AUTOSAR XML (schema 4-2-1)
standard types defined: sint32, uint32, uint8, sint32_DataConstr, uint32_DataConstr, uint8_DataConstr, uint16
package /TARefApp0102_SystemPackage/Types
  impl type ECmpCmd: category=VALUE, base-type=DataTypes/uint8, compu {0=eCmpCmd_Init, 1=eCmpCmd_DeInit, 2=eCmpCmd_Activate, 3=eCmpCmd_DeActivate, 4=eCmpCmd_Reset, 5=eCmpCmd_ReStart, 6=eCmpCmd_ExternalCount, 7=eCmpCmd_DiagStart, 8=eCmpCmd_DiagStop, 9=eCmpCmd_Count}, range raw 0..9
package /ZARXML_CMP
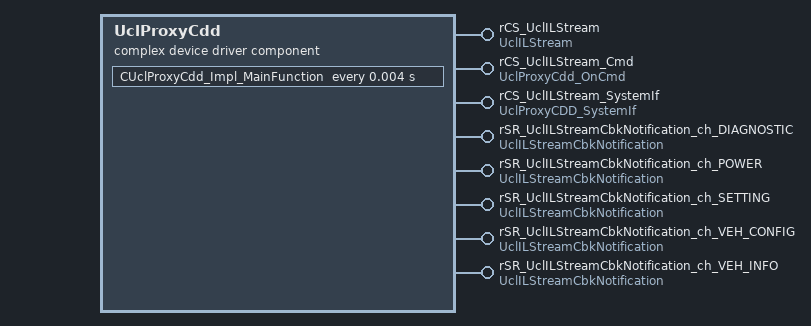
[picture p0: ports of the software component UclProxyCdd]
  complex device driver sw component type UclProxyCdd
    8 x provide port:
      rCS_UclILStream: provided-interface=UclILStream
        provided-com-specs:
          operation=close, queue-length=1
          operation=ioctl_flushRxQueue, queue-length=1
          operation=ioctl_flushTxQueue, queue-length=1
          operation=ioctl_getChParam, queue-length=1
          operation=ioctl_getLinkStatus, queue-length=1
          operation=ioctl_getStats, queue-length=1
          operation=ioctl_setChParam, queue-length=1
          operation=open, queue-length=1
          operation=poll, queue-length=1
          operation=read, queue-length=1
          operation=write, queue-length=1
          operation=write_ex, queue-length=1
      rCS_UclILStream_Cmd: server-com-spec{operation=Impl_OnCommand, queue-length=1}, provided-interface=UclProxyCdd_OnCmd
      rCS_UclILStream_SystemIf: provided-interface=UclProxyCDD_SystemIf
        provided-com-specs:
          operation=UclProxyCdd_Impl_Initialize, queue-length=1
          operation=UclProxyCdd_Impl_Shutdown, queue-length=1
      rSR_UclILStreamCbkNotification_ch_DIAGNOSTIC: provided-com-specs=[data-element=errStatus, data-element=linkStatus, data-element=rxNotification, data-element=txStatus], provided-interface=UclILStreamCbkNotification
      rSR_UclILStreamCbkNotification_ch_POWER: provided-com-specs=[data-element=errStatus, data-element=linkStatus, data-element=rxNotification, data-element=txStatus], provided-interface=UclILStreamCbkNotification
      rSR_UclILStreamCbkNotification_ch_SETTING: provided-com-specs=[data-element=errStatus, data-element=linkStatus, data-element=rxNotification, data-element=txStatus], provided-interface=UclILStreamCbkNotification
      rSR_UclILStreamCbkNotification_ch_VEH_CONFIG: provided-com-specs=[data-element=errStatus, data-element=linkStatus, data-element=rxNotification, data-element=txStatus], provided-interface=UclILStreamCbkNotification
      rSR_UclILStreamCbkNotification_ch_VEH_INFO: provided-com-specs=[data-element=errStatus, data-element=linkStatus, data-element=rxNotification, data-element=txStatus], provided-interface=UclILStreamCbkNotification
    behavior UclProxyCdd_IB
      8 x operation invoked event:
        OIT_ucl_close_UclILStream_close: start-on-event=CUclProxyCdd_Impl_Close, operation=rCS_UclILStream.close
        OIT_CUclProxyCdd_Impl_Initialize_rCS_UclILStream_SystemIf_UclProxyCdd_Impl_Initialize: start-on-event=CUclProxyCdd_Impl_Initialize, operation=rCS_UclILStream_SystemIf.UclProxyCdd_Impl_Initialize
        OIT_CUclProxyCdd_Impl_IoCtl_FlushRxQueue_rCS_UclILStream_ioctl_flushRxQueue: start-on-event=CUclProxyCdd_Impl_IoCtl_FlushRxQueue, operation=rCS_UclILStream.ioctl_flushRxQueue
        OIT_CUclProxyCdd_Impl_IoCtl_FlushTxQueue_rCS_UclILStream_ioctl_flushTxQueue: start-on-event=CUclProxyCdd_Impl_IoCtl_FlushTxQueue, operation=rCS_UclILStream.ioctl_flushTxQueue
        OIT_CUclProxyCdd_Impl_Ioctl_GetChParam_rCS_UclILStream_ioctl_getChParam: start-on-event=CUclProxyCdd_Impl_Ioctl_GetChParam, operation=rCS_UclILStream.ioctl_getChParam
        OIT_CUclProxyCdd_Impl_IoCtl_GetLinkStatus_rCS_UclILStream_ioctl_getLinkStatus: start-on-event=CUclProxyCdd_Impl_IoCtl_GetLinkStatus, operation=rCS_UclILStream.ioctl_getLinkStatus
        OIT_CUclProxyCdd_Impl_IoCtl_Req_Stats_rCS_UclILStream_ioctl_req_stats: start-on-event=CUclProxyCdd_Impl_IoCtl_GetStats, operation=rCS_UclILStream.ioctl_getStats
        OIT_CUclProxyCdd_Impl_Ioctl_RW_ChannelParam_rCS_UclILStream_ioctl_rw_chparam: start-on-event=CUclProxyCdd_Impl_Ioctl_SetChParam, operation=rCS_UclILStream.ioctl_setChParam
      timing event TE_UclProxyCdd_MainFunction: start-on-event=CUclProxyCdd_Impl_MainFunction, period=0.004
      7 x operation invoked event:
        OIT_CUclProxyCdd_Impl_OnCommand_rCS_UclILStream_Cmd_Impl_OnCommand: start-on-event=CUclProxyCdd_Impl_OnCommand, operation=rCS_UclILStream_Cmd.Impl_OnCommand
        OIT_ucl_open_UclILStream_open: start-on-event=CUclProxyCdd_Impl_Open, operation=rCS_UclILStream.open
        OIT_ucl_poll_UclILStream_poll: start-on-event=CUclProxyCdd_Impl_Poll, operation=rCS_UclILStream.poll
        OIT_ucl_read_UclILStream_read: start-on-event=CUclProxyCdd_Impl_Read, operation=rCS_UclILStream.read
        OIT_CUclProxyCdd_Impl_Shutdown_rCS_UclILStream_SystemIf_UclProxyCdd_Impl_Shutdown: start-on-event=CUclProxyCdd_Impl_Shutdown, operation=rCS_UclILStream_SystemIf.UclProxyCdd_Impl_Shutdown
        OIT_ucl_write_UclILStream_write: start-on-event=CUclProxyCdd_Impl_Write, operation=rCS_UclILStream.write
        OIT_ucl_write_ex_UclILStream_write_ex: start-on-event=CUclProxyCdd_Impl_Write_Ex, operation=rCS_UclILStream.write_ex
      port-api-options:
        enable-take-address=false, indirect-api=false, port=rCS_UclILStream
        enable-take-address=false, indirect-api=false, port=rCS_UclILStream_Cmd
        enable-take-address=false, indirect-api=false, port=rCS_UclILStream_SystemIf
        enable-take-address=false, indirect-api=false, port=rSR_UclILStreamCbkNotification_ch_DIAGNOSTIC
        enable-take-address=false, indirect-api=false, port=rSR_UclILStreamCbkNotification_ch_POWER
        enable-take-address=false, indirect-api=false, port=rSR_UclILStreamCbkNotification_ch_SETTING
        enable-take-address=false, indirect-api=false, port=rSR_UclILStreamCbkNotification_ch_VEH_CONFIG
        enable-take-address=false, indirect-api=false, port=rSR_UclILStreamCbkNotification_ch_VEH_INFO
      16 x runnable:
        CUclProxyCdd_Impl_Close  # /// /// @brief Close an UCL Channel /// /// @param[in] fd File descriptor returned by the open call /// @param[out] ret UCL_E_OK Successfully closed the channel /// @ref UCL_ERR ///
          data-send-points:
            8 x access:
              SEND_rSR_UclILStreamCbkNotification_Channel1_errStatus: accessed-variable=rSR_UclILStreamCbkNotification_ch_VEH_INFO.errStatus
              SEND_rSR_UclILStreamCbkNotification_Channel1_linkStatus: accessed-variable=rSR_UclILStreamCbkNotification_ch_VEH_INFO.linkStatus
              SEND_rSR_UclILStreamCbkNotification_Channel1_rxNotification: accessed-variable=rSR_UclILStreamCbkNotification_ch_VEH_INFO.rxNotification
              SEND_rSR_UclILStreamCbkNotification_Channel1_txStatus: accessed-variable=rSR_UclILStreamCbkNotification_ch_VEH_INFO.txStatus
              SEND_rSR_UclILStreamCbkNotification_Channel2_errStatus: accessed-variable=rSR_UclILStreamCbkNotification_ch_POWER.errStatus
              SEND_rSR_UclILStreamCbkNotification_Channel2_linkStatus: accessed-variable=rSR_UclILStreamCbkNotification_ch_POWER.linkStatus
              SEND_rSR_UclILStreamCbkNotification_Channel2_rxNotification: accessed-variable=rSR_UclILStreamCbkNotification_ch_POWER.rxNotification
              SEND_rSR_UclILStreamCbkNotification_Channel2_txStatus: accessed-variable=rSR_UclILStreamCbkNotification_ch_POWER.txStatus
        CUclProxyCdd_Impl_Initialize  # /// /// @Lifecycle Call : To intialize Ucl without using Cmplib ///
        CUclProxyCdd_Impl_IoCtl_FlushRxQueue
        CUclProxyCdd_Impl_IoCtl_FlushTxQueue
        CUclProxyCdd_Impl_Ioctl_GetChParam
        CUclProxyCdd_Impl_IoCtl_GetLinkStatus
        CUclProxyCdd_Impl_IoCtl_GetStats
        CUclProxyCdd_Impl_Ioctl_SetChParam
        CUclProxyCdd_Impl_MainFunction  # /// /// @brief Runnable for Ucl Timer Task. Internal to Ucl Cdd ///
          data-send-points:
            20 x access:
              SEND_rSR_UclILStreamCbkNotification_ch_DIAGNOSTIC_errStatus: accessed-variable=rSR_UclILStreamCbkNotification_ch_DIAGNOSTIC.errStatus
              SEND_rSR_UclILStreamCbkNotification_ch_DIAGNOSTIC_linkStatus: accessed-variable=rSR_UclILStreamCbkNotification_ch_DIAGNOSTIC.linkStatus
              SEND_rSR_UclILStreamCbkNotification_ch_DIAGNOSTIC_rxNotification: accessed-variable=rSR_UclILStreamCbkNotification_ch_DIAGNOSTIC.rxNotification
              SEND_rSR_UclILStreamCbkNotification_ch_DIAGNOSTIC_txStatus: accessed-variable=rSR_UclILStreamCbkNotification_ch_DIAGNOSTIC.txStatus
              SEND_rSR_UclILStreamCbkNotification_ch_SETTING_errStatus: accessed-variable=rSR_UclILStreamCbkNotification_ch_SETTING.errStatus
              SEND_rSR_UclILStreamCbkNotification_ch_SETTING_linkStatus: accessed-variable=rSR_UclILStreamCbkNotification_ch_SETTING.linkStatus
              SEND_rSR_UclILStreamCbkNotification_ch_SETTING_rxNotification: accessed-variable=rSR_UclILStreamCbkNotification_ch_SETTING.rxNotification
              SEND_rSR_UclILStreamCbkNotification_ch_SETTING_txStatus: accessed-variable=rSR_UclILStreamCbkNotification_ch_SETTING.txStatus
              SEND_rSR_UclILStreamCbkNotification_ch_VEH_CONFIG_errStatus: accessed-variable=rSR_UclILStreamCbkNotification_ch_VEH_CONFIG.errStatus
              SEND_rSR_UclILStreamCbkNotification_ch_VEH_CONFIG_linkStatus: accessed-variable=rSR_UclILStreamCbkNotification_ch_VEH_CONFIG.linkStatus
              SEND_rSR_UclILStreamCbkNotification_ch_VEH_CONFIG_rxNotification: accessed-variable=rSR_UclILStreamCbkNotification_ch_VEH_CONFIG.rxNotification
              SEND_rSR_UclILStreamCbkNotification_ch_VEH_CONFIG_txStatus: accessed-variable=rSR_UclILStreamCbkNotification_ch_VEH_CONFIG.txStatus
              SEND_rSR_UclILStreamCbkNotification_Channel2_errStatus: accessed-variable=rSR_UclILStreamCbkNotification_ch_POWER.errStatus
              SEND_rSR_UclILStreamCbkNotification_Channel2_linkStatus: accessed-variable=rSR_UclILStreamCbkNotification_ch_POWER.linkStatus
              SEND_rSR_UclILStreamCbkNotification_Channel2_rxNotification: accessed-variable=rSR_UclILStreamCbkNotification_ch_POWER.rxNotification
              SEND_rSR_UclILStreamCbkNotification_Channel2_txStatus: accessed-variable=rSR_UclILStreamCbkNotification_ch_POWER.txStatus
              SEND_rSR_UclILStreamCbkNotification_errStatus: accessed-variable=rSR_UclILStreamCbkNotification_ch_VEH_INFO.errStatus
              SEND_rSR_UclILStreamCbkNotification_linkStatus: accessed-variable=rSR_UclILStreamCbkNotification_ch_VEH_INFO.linkStatus
              SEND_rSR_UclILStreamCbkNotification_rxNotification: accessed-variable=rSR_UclILStreamCbkNotification_ch_VEH_INFO.rxNotification
              SEND_rSR_UclILStreamCbkNotification_txStatus: accessed-variable=rSR_UclILStreamCbkNotification_ch_VEH_INFO.txStatus
        CUclProxyCdd_Impl_OnCommand  # /// /// @brief Runnable for Life cycle calls. Applicable for AppCntrl/ Ecumext. ///
        CUclProxyCdd_Impl_Open  # /// @defgroup UCL_CHN_FUNC UCL Channel APIs /// @brief UCL Channel based APIs /// @{ /// /// @brief Open an UCL Channel /// /// @param[in] chId Channel Identifier /// @param[in] flags @ref UCL_O_FLAGS /// @param[out] fd fd >= 0 File descriptor to be used /// fd < 0 UCL_ERR
        CUclProxyCdd_Impl_Poll  # /// /// @brief Poll the UCL channel to check for receive data /// /// @param[in] fd File descriptor returned by the open call /// @param[in] timeout Timeout to wait for data /// /// @param[out] ret > 0 number of bytes waiting to be read /// ret < 0 @ref UCL_ERR
        CUclProxyCdd_Impl_Read  # /// /// @brief Read data from the UCL channel /// /// @param[in] fd File descriptor returned by the open call /// @param[out] pBuffer Buffer to return the received data /// @param[in] size Size of the buffer ///@param[out] ret return > 0 number of bytes read return < 0 @ref UCL_ERR
        CUclProxyCdd_Impl_Shutdown  # /// /// @Lifecycle Call : To shutdownUcl without using Cmplib ///
        CUclProxyCdd_Impl_Write  # /// /// @brief Write data to the UCL channel /// /// @param[in] fd File descriptor returned by the open call /// @param[in] pBuffer Buffer that contains the data to be sent /// @param[in] size Size of the buffer /// @param[out] ret > 0 number of bytes sent ret < 0 ref UCL_ERR
        CUclProxyCdd_Impl_Write_Ex  # /// /// @brief Write data to the UCL channel along with the request id /// /// @param[in] fd File descriptor returned by the open call /// @param[in] reqId Request ID to be associated with this write request /// @param[in] pBuffer Buffer that contains the data to be sent /// @param[in] size Size of the buffer /// @param[out] ret > 0 number of bytes sent /// ret < 0 @ref UCL_ERR
  swc implementation UclProxyCdd_Implementation: behavior=UclProxyCdd_IB
    code-descriptors:
      code Default: artifact-descriptors=autosar-engineering-object={short-label=Default, category=SWSRC}
package /ZARXML_DATA_TYPES
  7 x impl type, all with type-emitter=RTE:
    rte_ucl_ch_t: implementation-data-type=ZARXML_DATA_TYPES/uint8
    rte_ucl_fd_t: implementation-data-type=ZARXML_DATA_TYPES/sint32
    rte_ucl_flag_type: compu {1=UCL_O_RDONLY, 2=UCL_O_WRONLY, 4=UCL_O_RDWR, phys=raw for raw 8} "/// @defgroup UCL_O_FLAGS UCL Open flags /// @brief UCL Open flags to set the channel open mode /// @{ #define UCL_O_RDONLY (0x0001u) ///< open for reading only #define UCL_O_WRONLY (0x0002u) ///< open for writing only #define UCL_O_RDWR (0x0004u) ///< open for reading and writing #define UCL_O_SHARED (0x0008u) ///< open with shared mode /// @} /// @", implementation-data-type=uint16
    rte_ucl_ioctl_channel_param_t: category=STRUCTURE, sw-calibration-access=READ-ONLY, dynamic-array-size-profile=None
      element priority_level: compu {0=UCL_PRIORITY_LEVEL_CRI, 1=UCL_PRIORITY_LEVEL_HIG, 2=UCL_PRIORITY_LEVEL_MID, 3=UCL_PRIORITY_LEVEL_LOW} "#define UCL_PRIORITY_LEVEL_CRI (0u) ///< Priority level Critical #define UCL_PRIORITY_LEVEL_HIG (1u) ///< Priority level High #define UCL_PRIORITY_LEVEL_MID (2u) ///< Priority level Medium #define UCL_PRIORITY_LEVEL_LOW (3u) ///< Priority level Low", implementation-data-type=ZARXML_DATA_TYPES/uint8
      element security_level: compu {0=UCL_SECURITY_LEVEL_UNSECURE, 1=UCL_SECURITY_LEVEL_AUTHENTICATED, 2=UCL_SECURITY_LEVEL_ENCRYPTED, 3=UCL_SECURITY_LEVEL_RESERVED} "#define UCL_SECURITY_LEVEL_UNSECURE (0u) ///< Security level is unsecure #define UCL_SECURITY_LEVEL_AUTHENTICATED (1u) ///< Security level is authenticated #define UCL_SECURITY_LEVEL_ENCRYPTED (2u) ///< Security level is encrypted #define UCL_SECURITY_LEVEL_RESERVED (3u) ///< Reserved security level", implementation-data-type=ZARXML_DATA_TYPES/uint8
      element time_to_live_ms: implementation-data-type=uint16
    rte_ucl_ioctl_channel_stats_t: category=STRUCTURE, sw-calibration-access=READ-ONLY, dynamic-array-size-profile=None
      element dl: category=STRUCTURE, sw-calibration-access=READ-ONLY
        7 x element, all with category=TYPE_REFERENCE, implementation-data-type=ZARXML_DATA_TYPES/uint32:
          tx_bytes
          rx_bytes
          tx_msgs
          rx_msgs
          tx_kbps
          rx_kbps
          avg_ack_latency
      element il: category=STRUCTURE, sw-calibration-access=READ-ONLY
        element num_open_channels: implementation-data-type=ZARXML_DATA_TYPES/uint32
        element num_open_fds: implementation-data-type=ZARXML_DATA_TYPES/uint32
    SDKRxStatus: category=STRUCTURE, sw-calibration-access=READ-ONLY, dynamic-array-size-profile=None
      element fd: implementation-data-type=rte_ucl_fd_t
    SDKTxStatus: category=STRUCTURE, sw-calibration-access=READ-ONLY, dynamic-array-size-profile=None
      element fd: implementation-data-type=ZARXML_DATA_TYPES/sint32
      element reqId: implementation-data-type=ZARXML_DATA_TYPES/uint8
      element txStatus: implementation-data-type=ZARXML_DATA_TYPES/sint32
package /ZARXML_PORT_IF
  client server interface UclILStream  # /// /// @brief Close an UCL Channel /// /// @param[in] fd File descriptor returned by the open call /// @param[out] ret UCL_E_OK Successfully closed the channel /// @ref UCL_ERR ///
    12 x operation, all with possible-error=[UclILStream/E_NOK, UclILStream/E_OK]:
      close  # /// /// @brief Close an UCL Channel /// /// @param[in] fd File descriptor returned by the open call /// @param[out] ret UCL_E_OK Successfully closed the channel /// @ref UCL_ERR ///
        arg fd: type=rte_ucl_fd_t, direction=IN, server-argument-impl-policy=USE-ARGUMENT-TYPE
        arg ret: type=ZARXML_DATA_TYPES/sint32, direction=OUT, server-argument-impl-policy=USE-ARGUMENT-TYPE
      ioctl_flushRxQueue
        arg fd: type=rte_ucl_fd_t, direction=IN, server-argument-impl-policy=USE-ARGUMENT-TYPE
      ioctl_flushTxQueue
        arg fd: type=rte_ucl_fd_t, direction=IN, server-argument-impl-policy=USE-ARGUMENT-TYPE
      ioctl_getChParam
        arg fd: type=rte_ucl_fd_t, direction=IN, server-argument-impl-policy=USE-ARGUMENT-TYPE
        arg chParam: type=rte_ucl_ioctl_channel_param_t, direction=INOUT, server-argument-impl-policy=USE-ARGUMENT-TYPE
      ioctl_getLinkStatus
        arg fd: type=rte_ucl_fd_t, direction=IN, server-argument-impl-policy=USE-ARGUMENT-TYPE
        arg linkStatus: type=ImplementationDataTypes/sint32, direction=OUT, server-argument-impl-policy=USE-ARGUMENT-TYPE
      ioctl_getStats
        arg fd: type=rte_ucl_fd_t, direction=IN, server-argument-impl-policy=USE-ARGUMENT-TYPE
        arg stats: type=rte_ucl_ioctl_channel_stats_t, direction=OUT, server-argument-impl-policy=USE-ARGUMENT-TYPE
      ioctl_setChParam
        arg fd: type=rte_ucl_fd_t, direction=IN, server-argument-impl-policy=USE-ARGUMENT-TYPE
        arg chParam: type=rte_ucl_ioctl_channel_param_t, direction=IN, server-argument-impl-policy=USE-ARGUMENT-TYPE
      open  # /// @defgroup UCL_CHN_FUNC UCL Channel APIs /// @brief UCL Channel based APIs /// @{ /// /// @brief Open an UCL Channel /// /// @param[in] chId Channel Identifier /// @param[in] flags @ref UCL_O_FLAGS /// @param[out] fd fd >= 0 File descriptor to be used /// fd < 0 UCL_ERR
        arg chId: type=rte_ucl_ch_t, direction=IN, server-argument-impl-policy=USE-ARGUMENT-TYPE
        arg flags: type=rte_ucl_flag_type, direction=IN, server-argument-impl-policy=USE-ARGUMENT-TYPE
        arg fd: type=rte_ucl_fd_t, direction=OUT, server-argument-impl-policy=USE-ARGUMENT-TYPE
      poll  # /// /// @brief Poll the UCL channel to check for receive data /// /// @param[in] fd File descriptor returned by the open call /// @param[in] timeout Timeout to wait for data /// /// @param[out] ret > 0 number of bytes waiting to be read /// ret < 0 @ref UCL_ERR
        arg fd: type=rte_ucl_fd_t, direction=IN, server-argument-impl-policy=USE-ARGUMENT-TYPE
        arg timeout: type=ImplementationDataTypes/uint32, direction=IN, server-argument-impl-policy=USE-ARGUMENT-TYPE
        arg ret: type=ZARXML_DATA_TYPES/sint32, direction=OUT, server-argument-impl-policy=USE-ARGUMENT-TYPE
      read  # /// /// @brief Read data from the UCL channel /// /// @param[in] fd File descriptor returned by the open call /// @param[out] pBuffer Buffer to return the received data /// @param[in] size Size of the buffer ///@param[out] ret return > 0 number of bytes read return < 0 @ref UCL_ERR
        4 x arg, all with server-argument-impl-policy=USE-ARGUMENT-TYPE:
          fd: type=rte_ucl_fd_t, direction=IN
          pbuffer: type=ImplementationDataTypes/uint8, direction=OUT
          size: type=ImplementationDataTypes/uint32, direction=IN
          sizeRead: type=ZARXML_DATA_TYPES/sint32, direction=OUT
      write  # /// /// @brief Write data to the UCL channel /// /// @param[in] fd File descriptor returned by the open call /// @param[in] pBuffer Buffer that contains the data to be sent /// @param[in] size Size of the buffer /// @param[out] ret > 0 number of bytes sent ret < 0 ref UCL_ERR
        4 x arg, all with server-argument-impl-policy=USE-ARGUMENT-TYPE:
          fd: type=rte_ucl_fd_t, direction=IN
          pbuffer: type=ImplementationDataTypes/uint8, direction=INOUT
          size: type=ImplementationDataTypes/uint32, direction=IN
          byteWrote: type=ZARXML_DATA_TYPES/sint32, direction=OUT
      write_ex  # /// /// @brief Write data to the UCL channel along with the request id /// /// @param[in] fd File descriptor returned by the open call /// @param[in] reqId Request ID to be associated with this write request /// @param[in] pBuffer Buffer that contains the data to be sent /// @param[in] size Size of the buffer /// @param[out] ret > 0 number of bytes sent /// ret < 0 @ref UCL_ERR
        5 x arg, all with server-argument-impl-policy=USE-ARGUMENT-TYPE:
          fd: type=rte_ucl_fd_t, direction=IN
          reqId: type=ImplementationDataTypes/uint8, direction=IN
          pBuffer: type=ImplementationDataTypes/uint8, direction=INOUT
          size: type=ImplementationDataTypes/uint32, direction=IN
          byteWrote: type=ZARXML_DATA_TYPES/sint32, direction=OUT
    error E_NOK: error-code=1
    error E_OK: error-code=0
  client server interface UclProxyCdd_OnCmd
    operation Impl_OnCommand: possible-error=[UclProxyCdd_OnCmd/E_OK, UclProxyCdd_OnCmd/E_NOK]
      arg cmd: type=ECmpCmd, direction=IN, server-argument-impl-policy=USE-ARGUMENT-TYPE
    error E_NOK: error-code=1
    error E_OK: error-code=0
  client server interface UclProxyCDD_SystemIf  # /// /// @brief Runnable for Ucl Timer Task. Internal to Ucl Cdd ///
    operation UclProxyCdd_Impl_Initialize: possible-error=[UclProxyCDD_SystemIf/E_OK, UclProxyCDD_SystemIf/E_NOK]
    operation UclProxyCdd_Impl_Shutdown: possible-error=[UclProxyCDD_SystemIf/E_OK, UclProxyCDD_SystemIf/E_NOK]
    error E_NOK: error-code=1
    error E_OK: error-code=0
  sender receiver interface UclILStreamCbkNotification
    4 x data, all with sw-impl-policy=QUEUED:
      errStatus: type=ZARXML_DATA_TYPES/sint32
      linkStatus: type=ZARXML_DATA_TYPES/sint32
      rxNotification: type=SDKRxStatus
      txStatus: type=SDKTxStatus
    invalidation-policys:
      data-element=errStatus, handle-invalid=DONT-INVALIDATE
      data-element=linkStatus, handle-invalid=DONT-INVALIDATE
      data-element=rxNotification, handle-invalid=DONT-INVALIDATE
      data-element=txStatus, handle-invalid=DONT-INVALIDATE
